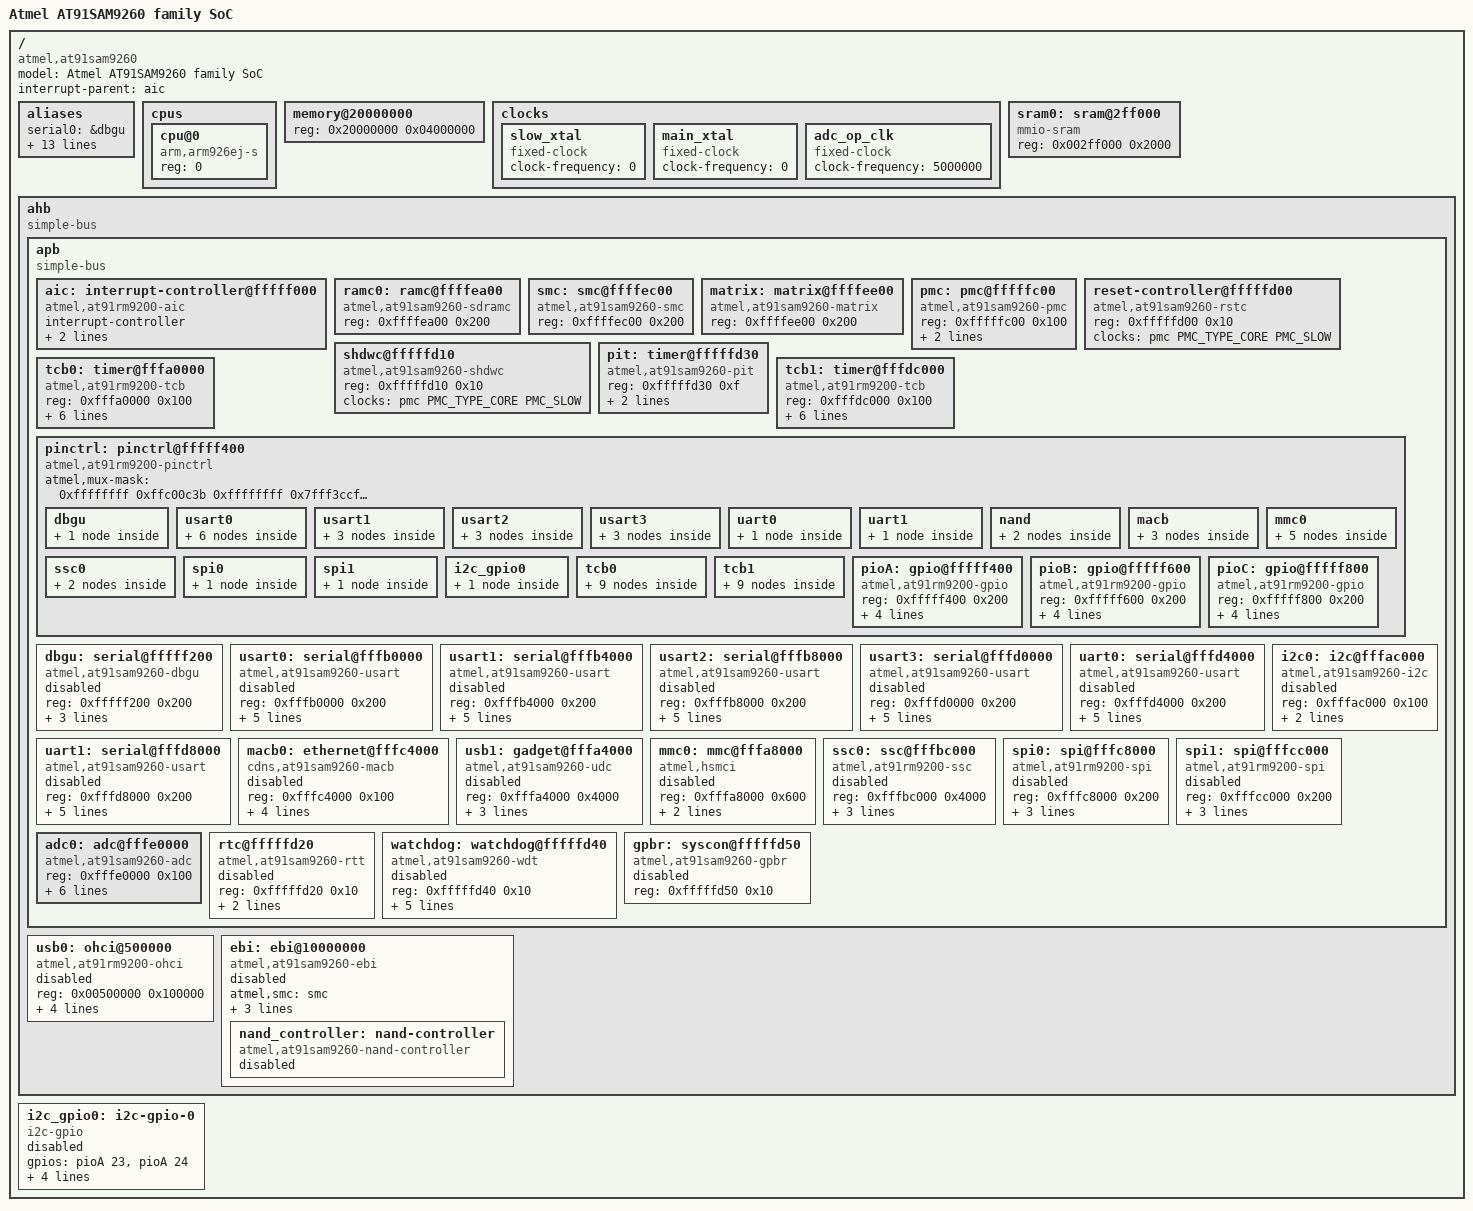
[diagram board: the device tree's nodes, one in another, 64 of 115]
// SPDX-License-Identifier: GPL-2.0-or-later
/*
 * at91sam9260.dtsi - Device Tree Include file for AT91SAM9260 family SoC
 *
 *  Copyright (C) 2011 Atmel,
 *                2011 Nicolas Ferre <nicolas.ferre@atmel.com>,
 *                2011 Jean-Christophe PLAGNIOL-VILLARD <plagnioj@jcrosoft.com>
 */

#include <dt-bindings/pinctrl/at91.h>
#include <dt-bindings/interrupt-controller/irq.h>
#include <dt-bindings/gpio/gpio.h>
#include <dt-bindings/clock/at91.h>

/ {
	#address-cells = <1>;
	#size-cells = <1>;
	model = "Atmel AT91SAM9260 family SoC";
	compatible = "atmel,at91sam9260";
	interrupt-parent = <&aic>;

	aliases {
		serial0 = &dbgu;
		serial1 = &usart0;
		serial2 = &usart1;
		serial3 = &usart2;
		serial4 = &usart3;
		serial5 = &uart0;
		serial6 = &uart1;
		gpio0 = &pioA;
		gpio1 = &pioB;
		gpio2 = &pioC;
		tcb0 = &tcb0;
		tcb1 = &tcb1;
		i2c0 = &i2c0;
		ssc0 = &ssc0;
	};
	cpus {
		#address-cells = <1>;
		#size-cells = <0>;

		cpu@0 {
			compatible = "arm,arm926ej-s";
			device_type = "cpu";
			reg = <0>;
		};
	};

	memory@20000000 {
		device_type = "memory";
		reg = <0x20000000 0x04000000>;
	};

	clocks {
		slow_xtal: slow_xtal {
			compatible = "fixed-clock";
			#clock-cells = <0>;
			clock-frequency = <0>;
		};

		main_xtal: main_xtal {
			compatible = "fixed-clock";
			#clock-cells = <0>;
			clock-frequency = <0>;
		};

		adc_op_clk: adc_op_clk{
			compatible = "fixed-clock";
			#clock-cells = <0>;
			clock-frequency = <5000000>;
		};
	};

	sram0: sram@2ff000 {
		compatible = "mmio-sram";
		reg = <0x002ff000 0x2000>;
		#address-cells = <1>;
		#size-cells = <1>;
		ranges = <0 0x002ff000 0x2000>;
	};

	ahb {
		compatible = "simple-bus";
		#address-cells = <1>;
		#size-cells = <1>;
		ranges;

		apb {
			compatible = "simple-bus";
			#address-cells = <1>;
			#size-cells = <1>;
			ranges;

			aic: interrupt-controller@fffff000 {
				#interrupt-cells = <3>;
				compatible = "atmel,at91rm9200-aic";
				interrupt-controller;
				reg = <0xfffff000 0x200>;
				atmel,external-irqs = <29 30 31>;
			};

			ramc0: ramc@ffffea00 {
				compatible = "atmel,at91sam9260-sdramc";
				reg = <0xffffea00 0x200>;
			};

			smc: smc@ffffec00 {
				compatible = "atmel,at91sam9260-smc", "syscon";
				reg = <0xffffec00 0x200>;
			};

			matrix: matrix@ffffee00 {
				compatible = "atmel,at91sam9260-matrix", "syscon";
				reg = <0xffffee00 0x200>;
			};

			pmc: pmc@fffffc00 {
				compatible = "atmel,at91sam9260-pmc", "syscon";
				reg = <0xfffffc00 0x100>;
				interrupts = <1 IRQ_TYPE_LEVEL_HIGH 7>;
				#clock-cells = <2>;
				clocks = <&slow_xtal>, <&main_xtal>;
				clock-names = "slow_xtal", "main_xtal";
			};

			reset-controller@fffffd00 {
				compatible = "atmel,at91sam9260-rstc";
				reg = <0xfffffd00 0x10>;
				clocks = <&pmc PMC_TYPE_CORE PMC_SLOW>;
			};

			shdwc@fffffd10 {
				compatible = "atmel,at91sam9260-shdwc";
				reg = <0xfffffd10 0x10>;
				clocks = <&pmc PMC_TYPE_CORE PMC_SLOW>;
			};

			pit: timer@fffffd30 {
				compatible = "atmel,at91sam9260-pit";
				reg = <0xfffffd30 0xf>;
				interrupts = <1 IRQ_TYPE_LEVEL_HIGH 7>;
				clocks = <&pmc PMC_TYPE_CORE PMC_MCK>;
			};

			tcb0: timer@fffa0000 {
				compatible = "atmel,at91rm9200-tcb", "simple-mfd", "syscon";
				#address-cells = <1>;
				#size-cells = <0>;
				reg = <0xfffa0000 0x100>;
				interrupts = <17 IRQ_TYPE_LEVEL_HIGH 0
					      18 IRQ_TYPE_LEVEL_HIGH 0
					      19 IRQ_TYPE_LEVEL_HIGH 0>;
				clocks = <&pmc PMC_TYPE_PERIPHERAL 17>, <&pmc PMC_TYPE_PERIPHERAL 18>, <&pmc PMC_TYPE_PERIPHERAL 19>, <&pmc PMC_TYPE_CORE PMC_SLOW>;
				clock-names = "t0_clk", "t1_clk", "t2_clk", "slow_clk";
			};

			tcb1: timer@fffdc000 {
				compatible = "atmel,at91rm9200-tcb", "simple-mfd", "syscon";
				#address-cells = <1>;
				#size-cells = <0>;
				reg = <0xfffdc000 0x100>;
				interrupts = <26 IRQ_TYPE_LEVEL_HIGH 0
					      27 IRQ_TYPE_LEVEL_HIGH 0
					      28 IRQ_TYPE_LEVEL_HIGH 0>;
				clocks = <&pmc PMC_TYPE_PERIPHERAL 26>, <&pmc PMC_TYPE_PERIPHERAL 27>, <&pmc PMC_TYPE_PERIPHERAL 28>, <&pmc PMC_TYPE_CORE PMC_SLOW>;
				clock-names = "t0_clk", "t1_clk", "t2_clk", "slow_clk";
			};

			pinctrl: pinctrl@fffff400 {
				#address-cells = <1>;
				#size-cells = <1>;
				compatible = "atmel,at91rm9200-pinctrl", "simple-bus";
				ranges = <0xfffff400 0xfffff400 0x600>;

				atmel,mux-mask = <
				      /*    A         B     */
				       0xffffffff 0xffc00c3b  /* pioA */
				       0xffffffff 0x7fff3ccf  /* pioB */
				       0xffffffff 0x007fffff  /* pioC */
				      >;

				/* shared pinctrl settings */
				dbgu {
					pinctrl_dbgu: dbgu-0 {
						atmel,pins =
							<AT91_PIOB 14 AT91_PERIPH_A AT91_PINCTRL_PULL_UP
							 AT91_PIOB 15 AT91_PERIPH_A AT91_PINCTRL_NONE>;
					};
				};

				usart0 {
					pinctrl_usart0: usart0-0 {
						atmel,pins =
							<AT91_PIOB 4 AT91_PERIPH_A AT91_PINCTRL_PULL_UP
							 AT91_PIOB 5 AT91_PERIPH_A AT91_PINCTRL_PULL_UP>;
					};

					pinctrl_usart0_rts: usart0_rts-0 {
						atmel,pins =
							<AT91_PIOB 26 AT91_PERIPH_A AT91_PINCTRL_NONE>;	/* PB26 periph A */
					};

					pinctrl_usart0_cts: usart0_cts-0 {
						atmel,pins =
							<AT91_PIOB 27 AT91_PERIPH_A AT91_PINCTRL_NONE>;	/* PB27 periph A */
					};

					pinctrl_usart0_dtr_dsr: usart0_dtr_dsr-0 {
						atmel,pins =
							<AT91_PIOB 24 AT91_PERIPH_A AT91_PINCTRL_NONE	/* PB24 periph A */
							 AT91_PIOB 22 AT91_PERIPH_A AT91_PINCTRL_NONE>;	/* PB22 periph A */
					};

					pinctrl_usart0_dcd: usart0_dcd-0 {
						atmel,pins =
							<AT91_PIOB 23 AT91_PERIPH_A AT91_PINCTRL_NONE>;	/* PB23 periph A */
					};

					pinctrl_usart0_ri: usart0_ri-0 {
						atmel,pins =
							<AT91_PIOB 25 AT91_PERIPH_A AT91_PINCTRL_NONE>;	/* PB25 periph A */
					};
				};

				usart1 {
					pinctrl_usart1: usart1-0 {
						atmel,pins =
							<AT91_PIOB 6 AT91_PERIPH_A AT91_PINCTRL_PULL_UP
							 AT91_PIOB 7 AT91_PERIPH_A AT91_PINCTRL_PULL_UP>;
					};

					pinctrl_usart1_rts: usart1_rts-0 {
						atmel,pins =
							<AT91_PIOB 28 AT91_PERIPH_A AT91_PINCTRL_NONE>;	/* PB28 periph A */
					};

					pinctrl_usart1_cts: usart1_cts-0 {
						atmel,pins =
							<AT91_PIOB 29 AT91_PERIPH_A AT91_PINCTRL_NONE>;	/* PB29 periph A */
					};
				};

				usart2 {
					pinctrl_usart2: usart2-0 {
						atmel,pins =
							<AT91_PIOB 8 AT91_PERIPH_A AT91_PINCTRL_PULL_UP
							 AT91_PIOB 9 AT91_PERIPH_A AT91_PINCTRL_PULL_UP>;
					};

					pinctrl_usart2_rts: usart2_rts-0 {
						atmel,pins =
							<AT91_PIOA 4 AT91_PERIPH_A AT91_PINCTRL_NONE>;	/* PA4 periph A */
					};

					pinctrl_usart2_cts: usart2_cts-0 {
						atmel,pins =
							<AT91_PIOA 5 AT91_PERIPH_A AT91_PINCTRL_NONE>;	/* PA5 periph A */
					};
				};

				usart3 {
					pinctrl_usart3: usart3-0 {
						atmel,pins =
							<AT91_PIOB 10 AT91_PERIPH_A AT91_PINCTRL_PULL_UP
							 AT91_PIOB 11 AT91_PERIPH_A AT91_PINCTRL_PULL_UP>;
					};

					pinctrl_usart3_rts: usart3_rts-0 {
						atmel,pins =
							<AT91_PIOC 8 AT91_PERIPH_B AT91_PINCTRL_NONE>;
					};

					pinctrl_usart3_cts: usart3_cts-0 {
						atmel,pins =
							<AT91_PIOC 10 AT91_PERIPH_B AT91_PINCTRL_NONE>;
					};
				};

				uart0 {
					pinctrl_uart0: uart0-0 {
						atmel,pins =
							<AT91_PIOA 31 AT91_PERIPH_B AT91_PINCTRL_PULL_UP
							 AT91_PIOA 30 AT91_PERIPH_B AT91_PINCTRL_PULL_UP>;
					};
				};

				uart1 {
					pinctrl_uart1: uart1-0 {
						atmel,pins =
							<AT91_PIOB 12 AT91_PERIPH_A AT91_PINCTRL_PULL_UP
							 AT91_PIOB 13 AT91_PERIPH_A AT91_PINCTRL_PULL_UP>;
					};
				};

				nand {
					pinctrl_nand_rb: nand-rb-0 {
						atmel,pins =
							<AT91_PIOC 13 AT91_PERIPH_GPIO AT91_PINCTRL_PULL_UP>;
					};

					pinctrl_nand_cs: nand-cs-0 {
						atmel,pins =
							 <AT91_PIOC 14 AT91_PERIPH_GPIO AT91_PINCTRL_PULL_UP>;
					};
				};

				macb {
					pinctrl_macb_rmii: macb_rmii-0 {
						atmel,pins =
							<AT91_PIOA 12 AT91_PERIPH_A AT91_PINCTRL_NONE	/* PA12 periph A */
							 AT91_PIOA 13 AT91_PERIPH_A AT91_PINCTRL_NONE	/* PA13 periph A */
							 AT91_PIOA 14 AT91_PERIPH_A AT91_PINCTRL_NONE	/* PA14 periph A */
							 AT91_PIOA 15 AT91_PERIPH_A AT91_PINCTRL_NONE	/* PA15 periph A */
							 AT91_PIOA 16 AT91_PERIPH_A AT91_PINCTRL_NONE	/* PA16 periph A */
							 AT91_PIOA 17 AT91_PERIPH_A AT91_PINCTRL_NONE	/* PA17 periph A */
							 AT91_PIOA 18 AT91_PERIPH_A AT91_PINCTRL_NONE	/* PA18 periph A */
							 AT91_PIOA 19 AT91_PERIPH_A AT91_PINCTRL_NONE	/* PA19 periph A */
							 AT91_PIOA 20 AT91_PERIPH_A AT91_PINCTRL_NONE	/* PA20 periph A */
							 AT91_PIOA 21 AT91_PERIPH_A AT91_PINCTRL_NONE>;	/* PA21 periph A */
					};

					pinctrl_macb_rmii_mii: macb_rmii_mii-0 {
						atmel,pins =
							<AT91_PIOA 22 AT91_PERIPH_B AT91_PINCTRL_NONE	/* PA22 periph B */
							 AT91_PIOA 23 AT91_PERIPH_B AT91_PINCTRL_NONE	/* PA23 periph B */
							 AT91_PIOA 24 AT91_PERIPH_B AT91_PINCTRL_NONE	/* PA24 periph B */
							 AT91_PIOA 25 AT91_PERIPH_B AT91_PINCTRL_NONE	/* PA25 periph B */
							 AT91_PIOA 26 AT91_PERIPH_B AT91_PINCTRL_NONE	/* PA26 periph B */
							 AT91_PIOA 27 AT91_PERIPH_B AT91_PINCTRL_NONE	/* PA27 periph B */
							 AT91_PIOA 28 AT91_PERIPH_B AT91_PINCTRL_NONE	/* PA28 periph B */
							 AT91_PIOA 29 AT91_PERIPH_B AT91_PINCTRL_NONE>;	/* PA29 periph B */
					};

					pinctrl_macb_rmii_mii_alt: macb_rmii_mii-1 {
						atmel,pins =
							<AT91_PIOA 10 AT91_PERIPH_B AT91_PINCTRL_NONE	/* PA10 periph B */
							 AT91_PIOA 11 AT91_PERIPH_B AT91_PINCTRL_NONE	/* PA11 periph B */
							 AT91_PIOA 22 AT91_PERIPH_B AT91_PINCTRL_NONE	/* PA22 periph B */
							 AT91_PIOA 25 AT91_PERIPH_B AT91_PINCTRL_NONE	/* PA25 periph B */
							 AT91_PIOA 26 AT91_PERIPH_B AT91_PINCTRL_NONE	/* PA26 periph B */
							 AT91_PIOA 27 AT91_PERIPH_B AT91_PINCTRL_NONE	/* PA27 periph B */
							 AT91_PIOA 28 AT91_PERIPH_B AT91_PINCTRL_NONE	/* PA28 periph B */
							 AT91_PIOA 29 AT91_PERIPH_B AT91_PINCTRL_NONE>;	/* PA29 periph B */
					};
				};

				mmc0 {
					pinctrl_mmc0_clk: mmc0_clk-0 {
						atmel,pins =
							<AT91_PIOA 8 AT91_PERIPH_A AT91_PINCTRL_NONE>;	/* PA8 periph A */
					};

					pinctrl_mmc0_slot0_cmd_dat0: mmc0_slot0_cmd_dat0-0 {
						atmel,pins =
							<AT91_PIOA 7 AT91_PERIPH_A AT91_PINCTRL_PULL_UP	/* PA7 periph A with pullup */
							 AT91_PIOA 6 AT91_PERIPH_A AT91_PINCTRL_PULL_UP>;	/* PA6 periph A with pullup */
					};

					pinctrl_mmc0_slot0_dat1_3: mmc0_slot0_dat1_3-0 {
						atmel,pins =
							<AT91_PIOA 9 AT91_PERIPH_A AT91_PINCTRL_PULL_UP	/* PA9 periph A with pullup */
							 AT91_PIOA 10 AT91_PERIPH_A AT91_PINCTRL_PULL_UP	/* PA10 periph A with pullup */
							 AT91_PIOA 11 AT91_PERIPH_A AT91_PINCTRL_PULL_UP>;	/* PA11 periph A with pullup */
					};

					pinctrl_mmc0_slot1_cmd_dat0: mmc0_slot1_cmd_dat0-0 {
						atmel,pins =
							<AT91_PIOA 1 AT91_PERIPH_B AT91_PINCTRL_PULL_UP	/* PA1 periph B with pullup */
							 AT91_PIOA 0 AT91_PERIPH_B AT91_PINCTRL_PULL_UP>;	/* PA0 periph B with pullup */
					};

					pinctrl_mmc0_slot1_dat1_3: mmc0_slot1_dat1_3-0 {
						atmel,pins =
							<AT91_PIOA 5 AT91_PERIPH_B AT91_PINCTRL_PULL_UP	/* PA5 periph B with pullup */
							 AT91_PIOA 4 AT91_PERIPH_B AT91_PINCTRL_PULL_UP	/* PA4 periph B with pullup */
							 AT91_PIOA 3 AT91_PERIPH_B AT91_PINCTRL_PULL_UP>;	/* PA3 periph B with pullup */
					};
				};

				ssc0 {
					pinctrl_ssc0_tx: ssc0_tx-0 {
						atmel,pins =
							<AT91_PIOB 16 AT91_PERIPH_A AT91_PINCTRL_NONE	/* PB16 periph A */
							 AT91_PIOB 17 AT91_PERIPH_A AT91_PINCTRL_NONE	/* PB17 periph A */
							 AT91_PIOB 18 AT91_PERIPH_A AT91_PINCTRL_NONE>;	/* PB18 periph A */
					};

					pinctrl_ssc0_rx: ssc0_rx-0 {
						atmel,pins =
							<AT91_PIOB 19 AT91_PERIPH_A AT91_PINCTRL_NONE	/* PB19 periph A */
							 AT91_PIOB 20 AT91_PERIPH_A AT91_PINCTRL_NONE	/* PB20 periph A */
							 AT91_PIOB 21 AT91_PERIPH_A AT91_PINCTRL_NONE>;	/* PB21 periph A */
					};
				};

				spi0 {
					pinctrl_spi0: spi0-0 {
						atmel,pins =
							<AT91_PIOA 0 AT91_PERIPH_A AT91_PINCTRL_NONE	/* PA0 periph A SPI0_MISO pin */
							 AT91_PIOA 1 AT91_PERIPH_A AT91_PINCTRL_NONE	/* PA1 periph A SPI0_MOSI pin */
							 AT91_PIOA 2 AT91_PERIPH_A AT91_PINCTRL_NONE>;	/* PA2 periph A SPI0_SPCK pin */
					};
				};

				spi1 {
					pinctrl_spi1: spi1-0 {
						atmel,pins =
							<AT91_PIOB 0 AT91_PERIPH_A AT91_PINCTRL_NONE	/* PB0 periph A SPI1_MISO pin */
							 AT91_PIOB 1 AT91_PERIPH_A AT91_PINCTRL_NONE	/* PB1 periph A SPI1_MOSI pin */
							 AT91_PIOB 2 AT91_PERIPH_A AT91_PINCTRL_NONE>;	/* PB2 periph A SPI1_SPCK pin */
					};
				};

				i2c_gpio0 {
					pinctrl_i2c_gpio0: i2c_gpio0-0 {
						atmel,pins =
							<AT91_PIOA 23 AT91_PERIPH_GPIO AT91_PINCTRL_MULTI_DRIVE
							 AT91_PIOA 24 AT91_PERIPH_GPIO AT91_PINCTRL_MULTI_DRIVE>;
					};
				};

				tcb0 {
					pinctrl_tcb0_tclk0: tcb0_tclk0-0 {
						atmel,pins = <AT91_PIOA 25 AT91_PERIPH_A AT91_PINCTRL_NONE>;
					};

					pinctrl_tcb0_tclk1: tcb0_tclk1-0 {
						atmel,pins = <AT91_PIOB 6 AT91_PERIPH_B AT91_PINCTRL_NONE>;
					};

					pinctrl_tcb0_tclk2: tcb0_tclk2-0 {
						atmel,pins = <AT91_PIOB 7 AT91_PERIPH_B AT91_PINCTRL_NONE>;
					};

					pinctrl_tcb0_tioa0: tcb0_tioa0-0 {
						atmel,pins = <AT91_PIOA 26 AT91_PERIPH_A AT91_PINCTRL_NONE>;
					};

					pinctrl_tcb0_tioa1: tcb0_tioa1-0 {
						atmel,pins = <AT91_PIOA 27 AT91_PERIPH_A AT91_PINCTRL_NONE>;
					};

					pinctrl_tcb0_tioa2: tcb0_tioa2-0 {
						atmel,pins = <AT91_PIOA 28 AT91_PERIPH_A AT91_PINCTRL_NONE>;
					};

					pinctrl_tcb0_tiob0: tcb0_tiob0-0 {
						atmel,pins = <AT91_PIOC 9 AT91_PERIPH_B AT91_PINCTRL_NONE>;
					};

					pinctrl_tcb0_tiob1: tcb0_tiob1-0 {
						atmel,pins = <AT91_PIOC 7 AT91_PERIPH_A AT91_PINCTRL_NONE>;
					};

					pinctrl_tcb0_tiob2: tcb0_tiob2-0 {
						atmel,pins = <AT91_PIOC 6 AT91_PERIPH_A AT91_PINCTRL_NONE>;
					};
				};

				tcb1 {
					pinctrl_tcb1_tclk0: tcb1_tclk0-0 {
						atmel,pins = <AT91_PIOB 16 AT91_PERIPH_B AT91_PINCTRL_NONE>;
					};

					pinctrl_tcb1_tclk1: tcb1_tclk1-0 {
						atmel,pins = <AT91_PIOB 17 AT91_PERIPH_B AT91_PINCTRL_NONE>;
					};

					pinctrl_tcb1_tclk2: tcb1_tclk2-0 {
						atmel,pins = <AT91_PIOC 22 AT91_PERIPH_B AT91_PINCTRL_NONE>;
					};

					pinctrl_tcb1_tioa0: tcb1_tioa0-0 {
						atmel,pins = <AT91_PIOB 0 AT91_PERIPH_B AT91_PINCTRL_NONE>;
					};

					pinctrl_tcb1_tioa1: tcb1_tioa1-0 {
						atmel,pins = <AT91_PIOB 2 AT91_PERIPH_B AT91_PINCTRL_NONE>;
					};

					pinctrl_tcb1_tioa2: tcb1_tioa2-0 {
						atmel,pins = <AT91_PIOB 3 AT91_PERIPH_B AT91_PINCTRL_NONE>;
					};

					pinctrl_tcb1_tiob0: tcb1_tiob0-0 {
						atmel,pins = <AT91_PIOB 1 AT91_PERIPH_B AT91_PINCTRL_NONE>;
					};

					pinctrl_tcb1_tiob1: tcb1_tiob1-0 {
						atmel,pins = <AT91_PIOB 18 AT91_PERIPH_B AT91_PINCTRL_NONE>;
					};

					pinctrl_tcb1_tiob2: tcb1_tiob2-0 {
						atmel,pins = <AT91_PIOB 19 AT91_PERIPH_B AT91_PINCTRL_NONE>;
					};
				};

				pioA: gpio@fffff400 {
					compatible = "atmel,at91rm9200-gpio";
					reg = <0xfffff400 0x200>;
					interrupts = <2 IRQ_TYPE_LEVEL_HIGH 1>;
					#gpio-cells = <2>;
					gpio-controller;
					interrupt-controller;
					#interrupt-cells = <2>;
					clocks = <&pmc PMC_TYPE_PERIPHERAL 2>;
				};

				pioB: gpio@fffff600 {
					compatible = "atmel,at91rm9200-gpio";
					reg = <0xfffff600 0x200>;
					interrupts = <3 IRQ_TYPE_LEVEL_HIGH 1>;
					#gpio-cells = <2>;
					gpio-controller;
					interrupt-controller;
					#interrupt-cells = <2>;
					clocks = <&pmc PMC_TYPE_PERIPHERAL 3>;
				};

				pioC: gpio@fffff800 {
					compatible = "atmel,at91rm9200-gpio";
					reg = <0xfffff800 0x200>;
					interrupts = <4 IRQ_TYPE_LEVEL_HIGH 1>;
					#gpio-cells = <2>;
					gpio-controller;
					interrupt-controller;
					#interrupt-cells = <2>;
					clocks = <&pmc PMC_TYPE_PERIPHERAL 4>;
				};
			};

			dbgu: serial@fffff200 {
				compatible = "atmel,at91sam9260-dbgu", "atmel,at91sam9260-usart";
				reg = <0xfffff200 0x200>;
				interrupts = <1 IRQ_TYPE_LEVEL_HIGH 7>;
				pinctrl-names = "default";
				pinctrl-0 = <&pinctrl_dbgu>;
				clocks = <&pmc PMC_TYPE_CORE PMC_MCK>;
				clock-names = "usart";
				status = "disabled";
			};

			usart0: serial@fffb0000 {
				compatible = "atmel,at91sam9260-usart";
				reg = <0xfffb0000 0x200>;
				interrupts = <6 IRQ_TYPE_LEVEL_HIGH 5>;
				atmel,use-dma-rx;
				atmel,use-dma-tx;
				pinctrl-names = "default";
				pinctrl-0 = <&pinctrl_usart0>;
				clocks = <&pmc PMC_TYPE_PERIPHERAL 6>;
				clock-names = "usart";
				status = "disabled";
			};

			usart1: serial@fffb4000 {
				compatible = "atmel,at91sam9260-usart";
				reg = <0xfffb4000 0x200>;
				interrupts = <7 IRQ_TYPE_LEVEL_HIGH 5>;
				atmel,use-dma-rx;
				atmel,use-dma-tx;
				pinctrl-names = "default";
				pinctrl-0 = <&pinctrl_usart1>;
				clocks = <&pmc PMC_TYPE_PERIPHERAL 7>;
				clock-names = "usart";
				status = "disabled";
			};

			usart2: serial@fffb8000 {
				compatible = "atmel,at91sam9260-usart";
				reg = <0xfffb8000 0x200>;
				interrupts = <8 IRQ_TYPE_LEVEL_HIGH 5>;
				atmel,use-dma-rx;
				atmel,use-dma-tx;
				pinctrl-names = "default";
				pinctrl-0 = <&pinctrl_usart2>;
				clocks = <&pmc PMC_TYPE_PERIPHERAL 8>;
				clock-names = "usart";
				status = "disabled";
			};

			usart3: serial@fffd0000 {
				compatible = "atmel,at91sam9260-usart";
				reg = <0xfffd0000 0x200>;
				interrupts = <23 IRQ_TYPE_LEVEL_HIGH 5>;
				atmel,use-dma-rx;
				atmel,use-dma-tx;
				pinctrl-names = "default";
				pinctrl-0 = <&pinctrl_usart3>;
				clocks = <&pmc PMC_TYPE_PERIPHERAL 23>;
				clock-names = "usart";
				status = "disabled";
			};

			uart0: serial@fffd4000 {
				compatible = "atmel,at91sam9260-usart";
				reg = <0xfffd4000 0x200>;
				interrupts = <24 IRQ_TYPE_LEVEL_HIGH 5>;
				atmel,use-dma-rx;
				atmel,use-dma-tx;
				pinctrl-names = "default";
				pinctrl-0 = <&pinctrl_uart0>;
				clocks = <&pmc PMC_TYPE_PERIPHERAL 24>;
				clock-names = "usart";
				status = "disabled";
			};

			uart1: serial@fffd8000 {
				compatible = "atmel,at91sam9260-usart";
				reg = <0xfffd8000 0x200>;
				interrupts = <25 IRQ_TYPE_LEVEL_HIGH 5>;
				atmel,use-dma-rx;
				atmel,use-dma-tx;
				pinctrl-names = "default";
				pinctrl-0 = <&pinctrl_uart1>;
				clocks = <&pmc PMC_TYPE_PERIPHERAL 25>;
				clock-names = "usart";
				status = "disabled";
			};

			macb0: ethernet@fffc4000 {
				compatible = "cdns,at91sam9260-macb", "cdns,macb";
				reg = <0xfffc4000 0x100>;
				interrupts = <21 IRQ_TYPE_LEVEL_HIGH 3>;
				pinctrl-names = "default";
				pinctrl-0 = <&pinctrl_macb_rmii>;
				clocks = <&pmc PMC_TYPE_PERIPHERAL 21>, <&pmc PMC_TYPE_PERIPHERAL 21>;
				clock-names = "hclk", "pclk";
				status = "disabled";
			};

			usb1: gadget@fffa4000 {
				compatible = "atmel,at91sam9260-udc";
				reg = <0xfffa4000 0x4000>;
				interrupts = <10 IRQ_TYPE_LEVEL_HIGH 2>;
				clocks = <&pmc PMC_TYPE_PERIPHERAL 10>, <&pmc PMC_TYPE_SYSTEM 7>;
				clock-names = "pclk", "hclk";
				status = "disabled";
			};

			i2c0: i2c@fffac000 {
				compatible = "atmel,at91sam9260-i2c";
				reg = <0xfffac000 0x100>;
				interrupts = <11 IRQ_TYPE_LEVEL_HIGH 6>;
				#address-cells = <1>;
				#size-cells = <0>;
				clocks = <&pmc PMC_TYPE_PERIPHERAL 11>;
				status = "disabled";
			};

			mmc0: mmc@fffa8000 {
				compatible = "atmel,hsmci";
				reg = <0xfffa8000 0x600>;
				interrupts = <9 IRQ_TYPE_LEVEL_HIGH 0>;
				#address-cells = <1>;
				#size-cells = <0>;
				clocks = <&pmc PMC_TYPE_PERIPHERAL 9>;
				clock-names = "mci_clk";
				status = "disabled";
			};

			ssc0: ssc@fffbc000 {
				compatible = "atmel,at91rm9200-ssc";
				reg = <0xfffbc000 0x4000>;
				interrupts = <14 IRQ_TYPE_LEVEL_HIGH 5>;
				pinctrl-names = "default";
				pinctrl-0 = <&pinctrl_ssc0_tx &pinctrl_ssc0_rx>;
				clocks = <&pmc PMC_TYPE_PERIPHERAL 14>;
				clock-names = "pclk";
				status = "disabled";
			};

			spi0: spi@fffc8000 {
				#address-cells = <1>;
				#size-cells = <0>;
				compatible = "atmel,at91rm9200-spi";
				reg = <0xfffc8000 0x200>;
				interrupts = <12 IRQ_TYPE_LEVEL_HIGH 3>;
				pinctrl-names = "default";
				pinctrl-0 = <&pinctrl_spi0>;
				clocks = <&pmc PMC_TYPE_PERIPHERAL 12>;
				clock-names = "spi_clk";
				status = "disabled";
			};

			spi1: spi@fffcc000 {
				#address-cells = <1>;
				#size-cells = <0>;
				compatible = "atmel,at91rm9200-spi";
				reg = <0xfffcc000 0x200>;
				interrupts = <13 IRQ_TYPE_LEVEL_HIGH 3>;
				pinctrl-names = "default";
				pinctrl-0 = <&pinctrl_spi1>;
				clocks = <&pmc PMC_TYPE_PERIPHERAL 13>;
				clock-names = "spi_clk";
				status = "disabled";
			};

			adc0: adc@fffe0000 {
				compatible = "atmel,at91sam9260-adc";
				reg = <0xfffe0000 0x100>;
				interrupts = <5 IRQ_TYPE_LEVEL_HIGH 0>;
				clocks = <&pmc PMC_TYPE_PERIPHERAL 5>, <&adc_op_clk>;
				clock-names = "adc_clk", "adc_op_clk";
				atmel,adc-use-external-triggers;
				atmel,adc-channels-used = <0xf>;
				atmel,adc-vref = <3300>;
				atmel,adc-startup-time = <15>;
			};

			rtc@fffffd20 {
				compatible = "atmel,at91sam9260-rtt";
				reg = <0xfffffd20 0x10>;
				interrupts = <1 IRQ_TYPE_LEVEL_HIGH 7>;
				clocks = <&pmc PMC_TYPE_CORE PMC_SLOW>;
				status = "disabled";
			};

			watchdog: watchdog@fffffd40 {
				compatible = "atmel,at91sam9260-wdt";
				reg = <0xfffffd40 0x10>;
				interrupts = <1 IRQ_TYPE_LEVEL_HIGH 7>;
				clocks = <&pmc PMC_TYPE_CORE PMC_SLOW>;
				atmel,watchdog-type = "hardware";
				atmel,reset-type = "all";
				atmel,dbg-halt;
				status = "disabled";
			};

			gpbr: syscon@fffffd50 {
				compatible = "atmel,at91sam9260-gpbr", "syscon";
				reg = <0xfffffd50 0x10>;
				status = "disabled";
			};
		};

		usb0: ohci@500000 {
			compatible = "atmel,at91rm9200-ohci", "usb-ohci";
			reg = <0x00500000 0x100000>;
			interrupts = <20 IRQ_TYPE_LEVEL_HIGH 2>;
			clocks = <&pmc PMC_TYPE_PERIPHERAL 20>, <&pmc PMC_TYPE_PERIPHERAL 20>, <&pmc PMC_TYPE_SYSTEM 6>;
			clock-names = "ohci_clk", "hclk", "uhpck";
			status = "disabled";
		};

		ebi: ebi@10000000 {
			compatible = "atmel,at91sam9260-ebi";
			#address-cells = <2>;
			#size-cells = <1>;
			atmel,smc = <&smc>;
			atmel,matrix = <&matrix>;
			reg = <0x10000000 0x80000000>;
			ranges = <0x0 0x0 0x10000000 0x10000000
				  0x1 0x0 0x20000000 0x10000000
				  0x2 0x0 0x30000000 0x10000000
				  0x3 0x0 0x40000000 0x10000000
				  0x4 0x0 0x50000000 0x10000000
				  0x5 0x0 0x60000000 0x10000000
				  0x6 0x0 0x70000000 0x10000000
				  0x7 0x0 0x80000000 0x10000000>;
			clocks = <&pmc PMC_TYPE_CORE PMC_MCK>;
			status = "disabled";

			nand_controller: nand-controller {
				compatible = "atmel,at91sam9260-nand-controller";
				#address-cells = <2>;
				#size-cells = <1>;
				ranges;
				status = "disabled";
			};
		};
	};

	i2c_gpio0: i2c-gpio-0 {
		compatible = "i2c-gpio";
		gpios = <&pioA 23 GPIO_ACTIVE_HIGH /* sda */
			 &pioA 24 GPIO_ACTIVE_HIGH /* scl */
			>;
		i2c-gpio,sda-open-drain;
		i2c-gpio,scl-open-drain;
		i2c-gpio,delay-us = <2>;	/* ~100 kHz */
		#address-cells = <1>;
		#size-cells = <0>;
		pinctrl-names = "default";
		pinctrl-0 = <&pinctrl_i2c_gpio0>;
		status = "disabled";
	};
};
